# ATmega8A device description
Architecture: AVR8; Family: megaAVR
Registers are 8-bit, access not given, no defined reset value unless marked. A register's access mark holds for its fields unless they carry their own. Offsets are from the block's base; [hi:lo] are bit positions; 'fields as' and 'values as' point back to an identical list.

## LOCKBIT — Lockbits
Instances: LOCKBIT 0 in lockbits
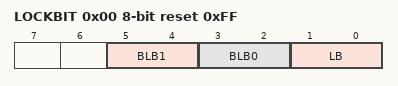
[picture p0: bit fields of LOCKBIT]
0x00 LOCKBIT reset 0xFF
  [5:4] BLB1 — Boot Loader Protection Mode
    0=LPM_SPM_DISABLE (LPM and SPM prohibited in Boot Section); 1=LPM_DISABLE (LPM prohibited in Boot Section); 2=SPM_DISABLE (SPM prohibited in Boot Section); 3=NO_LOCK (No lock on SPM and LPM in Boot Section)
  [3:2] BLB0 — Boot Loader Protection Mode
    0=LPM_SPM_DISABLE (LPM and SPM prohibited in Application Section); 1=LPM_DISABLE (LPM prohibited in Application Section); 2=SPM_DISABLE (SPM prohibited in Application Section); 3=NO_LOCK (No lock on SPM and LPM in Application Section)
  [1:0] LB — Memory Lock
    0=PROG_VER_DISABLED (Further programming and verification disabled); 2=PROG_DISABLED (Further programming disabled); 3=NO_LOCK (No memory lock features enabled)

## AC — Analog Comparator
Instances: AC 0x00
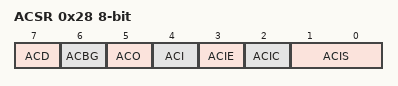
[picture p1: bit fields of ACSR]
0x28 ACSR — Analog Comparator Control And Status Register
  [7] ACD — Analog Comparator Disable
  [6] ACBG — Analog Comparator Bandgap Select
  [5] ACO — Analog Compare Output
  [4] ACI — Analog Comparator Interrupt Flag
  [3] ACIE — Analog Comparator Interrupt Enable
  [2] ACIC — Analog Comparator Input Capture Enable
  [1:0] ACIS — Analog Comparator Interrupt Mode Select bits
    0=Interrupt on Toggle; 2=Interrupt on Falling Edge; 3=Interrupt on Rising Edge
0x50 SFIOR — Special Function IO Register
  [3] ACME — Analog Comparator Multiplexer Enable

## SPI — Serial Peripheral Interface
Instances: SPI 0x00
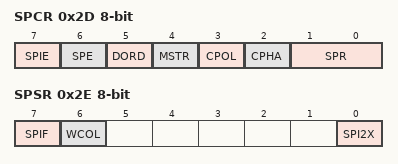
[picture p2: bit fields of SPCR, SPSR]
0x2D SPCR — SPI Control Register
  [7] SPIE — SPI Interrupt Enable
  [6] SPE — SPI Enable
  [5] DORD — Data Order
  [4] MSTR — Master/Slave Select
  [3] CPOL — Clock polarity
  [2] CPHA — Clock Phase
  [1:0] SPR — SPI Clock Rate Selects
    0=fosc/4; 1=fosc/16; 2=fosc/64; 3=fosc/128; 4=fosc/2; 5=fosc/8; 6=fosc/32; 7=fosc/64
0x2E SPSR — SPI Status Register
  [7] SPIF — SPI Interrupt Flag
  [6] WCOL — Write Collision Flag
  [0] SPI2X — Double SPI Speed Bit
0x2F SPDR — SPI Data Register

## EXINT — External Interrupts
Instances: EXINT 0x00
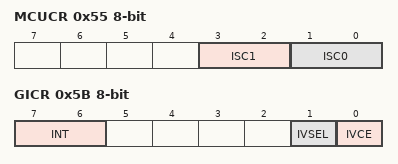
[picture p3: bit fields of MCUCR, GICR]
0x55 MCUCR — MCU Control Register
  [3:2] ISC1 — Interrupt Sense Control 1 Bits
    0=Low Level of INTX; 1=Any Logical Change of INTX; 2=Falling Edge of INTX; 3=Rising Edge of INTX
  [1:0] ISC0 — Interrupt Sense Control 0 Bits
    values as ISC1
0x5A GIFR — General Interrupt Flag Register
  [7:6] INTF — External Interrupt Flags
0x5B GICR — General Interrupt Control Register
  [7:6] INT — External Interrupt Request 1 Enable
  [1] IVSEL — Interrupt Vector Select
  [0] IVCE — Interrupt Vector Change Enable

## TC0 (TC8 module) — Timer/Counter, 8-bit
Instances: TC0 0x00
0x52 TCNT0 — Timer Counter 0
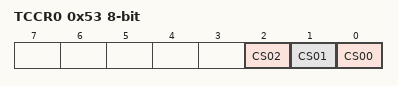
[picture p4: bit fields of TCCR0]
0x53 TCCR0 — Timer/Counter0 Control Register
  [2] CS02 — Clock Select0 bit 2
  [1] CS01 — Clock Select0 bit 1
  [0] CS00 — Clock Select0 bit 0
    0=No Clock Source (Stopped); 1=Running, No Prescaling; 2=Running, CLK/8; 3=Running, CLK/64; 4=Running, CLK/256; 5=Running, CLK/1024; 6=Running, ExtClk Tx Falling Edge; 7=Running, ExtClk Tx Rising Edge
0x58 TIFR — Timer/Counter Interrupt Flag register
  [0] TOV0 — Timer/Counter0 Overflow Flag
0x59 TIMSK — Timer/Counter Interrupt Mask Register
  [0] TOIE0 — Timer/Counter0 Overflow Interrupt Enable

## TC1 (TC16 module) — Timer/Counter, 16-bit
Instances: TC1 0x00
0x46 ICR1 16-bit — Timer/Counter1 Input Capture Register Bytes
0x48 OCR1B 16-bit — Timer/Counter1 Output Compare Register Bytes
0x4A OCR1A 16-bit — Timer/Counter1 Output Compare Register Bytes
0x4C TCNT1 16-bit — Timer/Counter1 Bytes
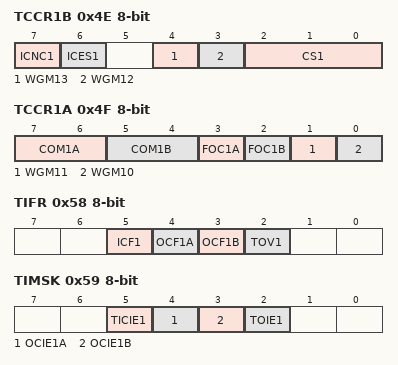
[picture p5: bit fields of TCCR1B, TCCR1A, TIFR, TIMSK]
0x4E TCCR1B — Timer/Counter1 Control Register B
  [7] ICNC1 — Input Capture 1 Noise Canceler
  [6] ICES1 — Input Capture 1 Edge Select
  [4] WGM13 (bit 2 of the value upward) — Waveform Generation Mode
  [3] WGM12 (bit 2 of the value upward) — Waveform Generation Mode
  [2:0] CS1 — Prescaler source of Timer/Counter 1
    0=No Clock Source (Stopped); 1=Running, No Prescaling; 2=Running, CLK/8; 3=Running, CLK/64; 4=Running, CLK/256; 5=Running, CLK/1024; 6=Running, ExtClk Tx Falling Edge; 7=Running, ExtClk Tx Rising Edge
0x4F TCCR1A — Timer/Counter1 Control Register A
  [7:6] COM1A — Compare Output Mode 1A, bits
  [5:4] COM1B — Compare Output Mode 1B, bits
  [3] FOC1A — Force Output Compare 1A
  [2] FOC1B — Force Output Compare 1B
  [1] WGM11 — Waveform Generation Mode
  [0] WGM10 — Waveform Generation Mode
0x58 TIFR — Timer/Counter Interrupt Flag register
  [5] ICF1 — Input Capture Flag 1
  [4] OCF1A — Output Compare Flag 1A
  [3] OCF1B — Output Compare Flag 1B
  [2] TOV1 — Timer/Counter1 Overflow Flag
0x59 TIMSK — Timer/Counter Interrupt Mask Register
  [5] TICIE1 — Timer/Counter1 Input Capture Interrupt Enable
  [4] OCIE1A — Timer/Counter1 Output CompareA Match Interrupt Enable
  [3] OCIE1B — Timer/Counter1 Output CompareB Match Interrupt Enable
  [2] TOIE1 — Timer/Counter1 Overflow Interrupt Enable
